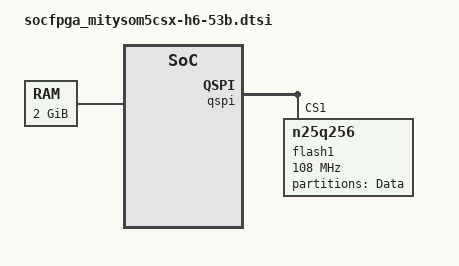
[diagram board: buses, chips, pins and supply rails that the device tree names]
#include "socfpga_mitysom5csx.dtsi"

/{
	memory {
		name = "memory";
		device_type = "memory";
		reg = <0x0 0x80000000>; /* 2 GB  */
	};
};

&qspi {
	flash1: nor@1 {
		#address-cells = <1>;
		#size-cells = <1>;
		compatible = "n25q256";
		reg = <1>;      /* chip select */
		spi-max-frequency = <108000000>;
		m25p,fast-read;
		page-size = <256>;
		block-size = <16>; /* 2^16, 64KB */
		read-delay = <4>;  /* delay value in read data capture register */
		tshsl-ns = <50>;
		tsd2d-ns = <50>;
		tchsh-ns = <4>;
		tslch-ns = <4>;

		partition@0 {
			/* 32MB for raw data. */
			label = "Data";
			reg = <0x0 0x2000000>;
		};
	};
};
